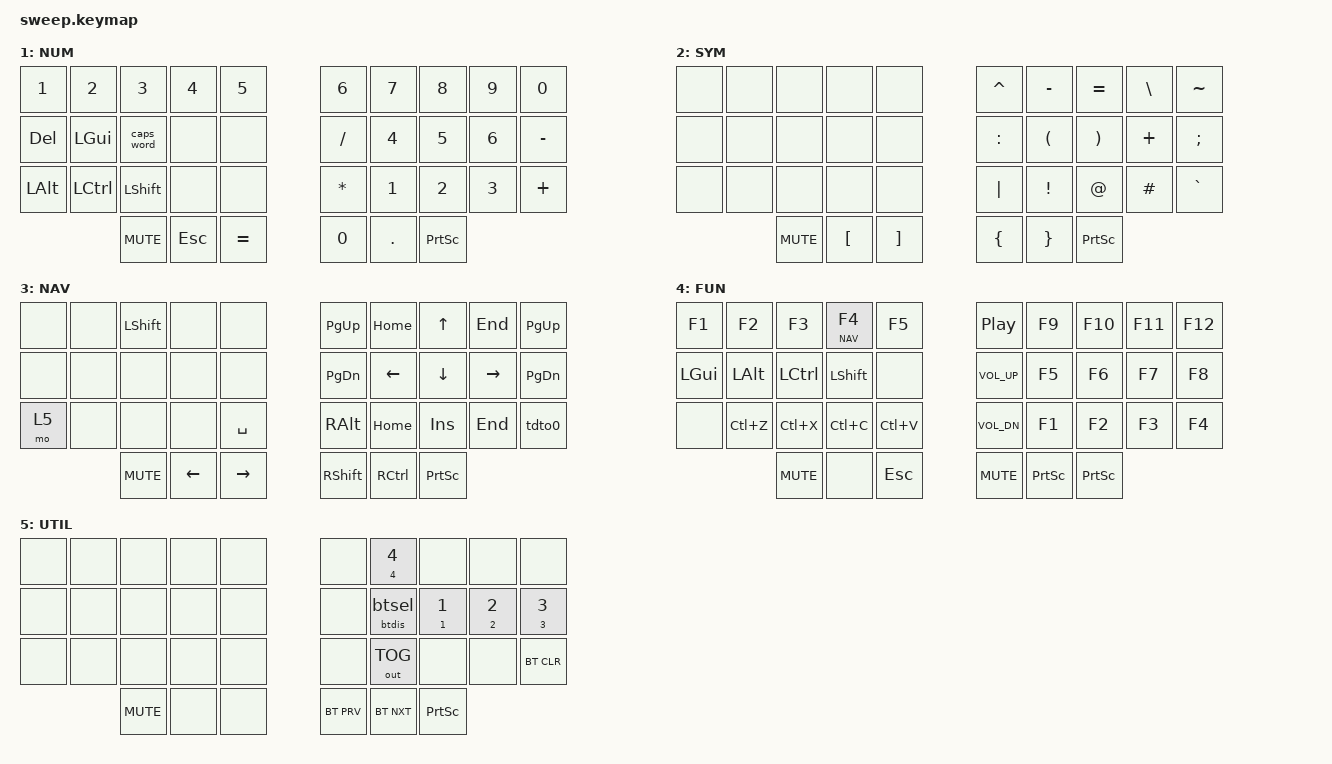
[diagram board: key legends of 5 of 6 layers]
// Copyright (c) 2022 The ZMK Contributors
// SPDX-License-Identifier: MIT
// #include <dt-bindings/zmk/rgb.h>

#define ZMK_POINTING_DEFAULT_MOVE_VAL 2500// 600
#define ZMK_POINTING_DEFAULT_SCRL_VAL 20// 10

#include <behaviors.dtsi>
#include <dt-bindings/zmk/bt.h>
#include <dt-bindings/zmk/keys.h>
#include <dt-bindings/zmk/outputs.h>
#include <dt-bindings/zmk/pointing.h>

#include "behaviors/character_map.dtsi"
#include "behaviors/report.dtsi"


#define ABC 0
#define NUM 1
#define SYM 2
#define NAV 3
#define FUN 4
#define UTIL 5

#define SPEED_POINTER 0
#define SPEED_SCROLL 1
#define SPEED_PREV 0
#define SPEED_NEXT 1
#define SPEED_RESET 2
#define SPEED_FINE_PREV 3
#define SPEED_FINE_NEXT 4
#define CIRQUE_MODE_RELATIVE 0
#define CIRQUE_MODE_ABSOLUTE 1
#define CIRQUE_MODE_TOGGLE 2

// Home row mods macro
#define HRML(k1,k2,k3,k4) &ht LGUI k1  &ht LALT k2  &ht LCTRL k3  &ht LSHFT k4
#define HRMR(k1,k2,k3,k4) &ht RSHFT k1  &ht RCTRL k2  &ht RALT k3  &ht RGUI k4

&sensors {
	left_encoder {
		triggers-per-rotation = <15>;
	};
	right_encoder {
		triggers-per-rotation = <45>;
	};
};

&glidepoint_listener {
	input-processors = <&pointer_processor 0 0 &drag_scroll_processor 1 8>;
};

/ {
	pointer_processor: pointer_processor {
		compatible = "zmk,input-processor-pointer-speed";
		#input-processor-cells = <2>;
		track-remainders;
		pointer-curve = "adaptive";
		pointer-curve-deadzone = <2>;
		pointer-curve-accel-multiplier = <1>;
		pointer-curve-accel-divisor = <12>;
		pointer-curve-max-delta = <120>;
		one-x-multiplier = <1>;
		one-x-divisor = <1>;
		min-percent = <10>;
		max-percent = <400>;
		initial-speed-position = <50>;
	};
	
	drag_scroll_processor: drag_scroll_processor {
		compatible = "zmk,input-processor-drag-scroll";
		#input-processor-cells = <2>;
		track-remainders;
		native-wheel-axis = "horizontal-when-enabled";
		scroll-min-step = <1>;
		one-x-multiplier = <1>;
		one-x-divisor = <1>;
		min-percent = <10>;
		max-percent = <1000>;
		initial-speed-position = <50>;
	};
	
	behaviors {
		drgscrl: drag_scroll {
			compatible = "zmk,behavior-drag-scroll";
			#binding-cells = <0>;
		};
	
		ptr_spd: pointing_speed {
			compatible = "zmk,behavior-pointing-speed";
			#binding-cells = <2>;
		};

		enc_ptr_spd: encoder_pointer_speed {
			compatible = "zmk,behavior-sensor-rotate";
			#sensor-binding-cells = <0>;
			bindings = <&ptr_spd SPEED_POINTER SPEED_PREV>, <&ptr_spd SPEED_POINTER SPEED_NEXT>;
		};

		enc_scrl_spd: encoder_scroll_speed {
			compatible = "zmk,behavior-sensor-rotate";
			#sensor-binding-cells = <0>;
			bindings = <&ptr_spd SPEED_SCROLL SPEED_PREV>, <&ptr_spd SPEED_SCROLL SPEED_NEXT>;
		};

		crq_mode: crqm {
			compatible = "zmk,behavior-cirque-mode";
			#binding-cells = <1>;
		};

		sel_x: select_x {
			compatible = "zmk,behavior-hold-tap";
			#binding-cells = <2>;
			flavor = "tap-preferred";
			tapping-term-ms = <200>;
			quick-tap-ms = <150>;
			require-prior-idle-ms = <125>;
			bindings = <&mkp>, <&kp>;
		};
		
		ds_z: drag_scroll_z {
			compatible = "zmk,behavior-hold-tap";
			#binding-cells = <2>;
			flavor = "tap-preferred";
			tapping-term-ms = <200>;
			quick-tap-ms = <150>;
			require-prior-idle-ms = <125>;
			bindings = <&drgscrl>, <&kp>;
		};

		ht: hold_tap {
			label = "hold_tap";
            compatible = "zmk,behavior-hold-tap";
            #binding-cells = <2>;
            flavor = "tap-preferred";
            tapping-term-ms = <180>;
            quick-tap-ms = <100>;
            require-prior-idle-ms = <100>;
            bindings = <&kp>, <&kp>;
        };
        btht: bluetooth_hold_tap {
            compatible = "zmk,behavior-hold-tap";
            #binding-cells = <2>;
            flavor = "tap-preferred";
            tapping-term-ms = <2000>;
            require-prior-idle-ms = <100>;
            bindings = <&btdis>, <&btsel>;
        };
        tdto0: tap_dance_to_layer_0 {
            compatible = "zmk,behavior-tap-dance";
            #binding-cells = <0>;
            tapping-term-ms = <200>;
            bindings = <&none>, <&to 0>;
        };
		mmv {
			acceleration-exponent = <1>;// 1
			time-to-max-speed-ms = <300>;// 40
			delay-ms = <0>;// 0
		};
		msc {
			acceleration-exponent = <0>;// 0
			time-to-max-speed-ms = <40>;// 500
			delay-ms = <0>;// 10
		};
	};
//End of behaviors

    macros {
        btsel: bluetooth_select {
            compatible = "zmk,behavior-macro-one-param";
            #binding-cells = <1>;
            bindings
                = <&macro_param_1to2>
                , <&macro_tap &bt BT_SEL MACRO_PLACEHOLDER>
                , <&macro_tap &out OUT_BLE>
                ;
        };
        btdis: bluetooth_disconnect {
            compatible = "zmk,behavior-macro-one-param";
            #binding-cells = <1>;
            bindings
                = <&macro_param_1to2>
                , <&macro_tap &bt BT_DISC MACRO_PLACEHOLDER>
                ;
        };
    };
//End of macros
	
	conditional_layers {
		compatible = "zmk,conditional-layers";
		
		tri_layer {
			if-layers = <NAV FUN>;
			then-layer = <UTIL>;
		};
	};

	combos {
		compatible = "zmk,combos";

		combo_fp_left_click {
			timeout-ms = <25>;
			require-prior-idle-ms = <125>;
			key-positions = <12 13>;
			layers = <ABC NUM NAV>;
			bindings = <&mkp RCLK>;
		};

		combo_cv_right_click {
			timeout-ms = <25>;
			require-prior-idle-ms = <125>;
			key-positions = <22 23>;
			layers = <ABC NUM NAV>;
			bindings = <&mkp RCLK>;
		};
        combo_caps_word {
            timeout-ms = <30>;
            key-positions = <2 3>;
            bindings = <&caps_word>;
        };
        combo_del {
            timeout-ms = <30>;
            key-positions = <6 7>;
            bindings = <&kp DEL>;
        };
        combo_esc {
            timeout-ms = <30>;
            key-positions = <0 1>;
            bindings = <&kp ESC>;
        };
        combo_navlock {
            timeout-ms = <30>;
            key-positions = <26 28>;
            bindings = <&to 3>;
        };
	};
//End of combos
	
	keymap {
		compatible = "zmk,keymap";

        default_layer {
			display-name = "ABC";
            bindings = <
        //╭──────────┬──────────┬──────────┬──────────┬──────────╮   ╭──────────┬──────────┬──────────┬──────────┬──────────╮
        //│  Q       │  W       │  F       │  P       │  B       │   │  J       │  L       │  U       │  Y       │ ' "      │
            &kp Q      &kp W      &kp F      &lt NAV P  &kp B          &kp J      &kp L      &kp U      &kp Y      &kp SQT
        //├──────────┼──────────┼──────────┼──────────┼──────────┤   ├──────────┼──────────┼──────────┼──────────┼──────────┤
        //│  A       │  R       │  S       │  T       │  G       │   │  M       │  N       │  E       │  I       │ O        │
            HRML(A,        R,         S,         T)     &kp G          &kp M      HRMR(N,        E,         I,        O)
        //├──────────┼──────────┼──────────┼──────────┼──────────┤   ├──────────┼──────────┼──────────┼──────────┼──────────┤
        //│  Z       │  X       │  C       │  D       │  V       │   │  K       │  H       │ , <      │ . >      │ / ?      │
            &lt FUN Z  &kp X      &lt SYM C  &lt NUM D  &kp V          &kp K      &kp H      &kp COMMA  &kp DOT    &kp FSLH
        //╰──────────┴──────────┴──────────┼──────────┼──────────┤   ├──────────┼──────────┼──────────┴──────────┴──────────╯
                        		 &kp C_MUTE  &kp TAB    &kp ENTER      &kp SPACE  &kp BSPC   &kp PSCRN
        //                      ╰──────────┴──────────┴──────────╯   ╰──────────┴──────────┴──────────╯
            >;
			sensor-bindings = <&inc_dec_kp C_VOL_DN C_VOL_UP &inc_dec_kp LEFT RIGHT>;
        };
		
        num_layer {
			display-name = "NUM";
            bindings = <
        //╭──────────┬──────────┬──────────┬──────────┬──────────╮   ╭──────────┬──────────┬──────────┬──────────┬──────────╮
        //│ 1        │ 2        │ 3        │ 4        │ 5        │   │ 6        │ 7        │ 8        │ 9        │  0       │
            &kp N1     &kp N2     &kp N3     &kp N4     &kp N5         &kp N6     &kp N7     &kp N8     &kp N9     &kp N0
        //├──────────┼──────────┼──────────┼──────────┼──────────┤   ├──────────┼──────────┼──────────┼──────────┼──────────┤
        //│ DELETE   │ WINDERS  │ CAPS     │          │          │   │ / ?      │ 4        │ 5        │ 6        │  -       │
            &kp DEL    &kp LGUI  &caps_word   &none      &none         &kp FSLH   &kp N4     &kp N5     &kp N6     &kp MINUS
        //├──────────┼──────────┼──────────┼──────────┼──────────┤   ├──────────┼──────────┼──────────┼──────────┼──────────┤
        //│          │          │          │This Layer│          │   │   *      │ 1        │ 2        │ 3        │  +       │
           &kp LALT   &kp LCTRL  &kp LSHFT   &none      &none         &kp ASTRK   &kp N1     &kp N2     &kp N3     &kp PLUS
        //╰──────────┴──────────┴──────────┼──────────┼──────────┤   ├──────────┼──────────┼──────────┴──────────┴──────────╯
                                 &kp C_MUTE  &kp ESC    &kp EQUAL       &kp N0     &kp DOT    &kp PSCRN
        //                      ╰──────────┴──────────┴──────────╯   ╰──────────┴──────────┴──────────╯
            >;
			sensor-bindings = <&inc_dec_kp C_VOL_DN C_VOL_UP &inc_dec_kp C_BRI_DEC C_BRI_UP>;
        };

        sym_layer {
			display-name = "SYM";
            bindings = <
        //╭──────────┬──────────┬──────────┬──────────┬──────────╮   ╭──────────┬──────────┬──────────┬──────────┬──────────╮
        //│          │          │          │          │          │   │  ^       │  -       │  =       │  \       │  ~       │
            &none      &none      &none     &none       &none          &kp CARET  &kp MINUS &kp EQUAL   &kp BSLH   &kp TILDE
        //├──────────┼──────────┼──────────┼──────────┼──────────┤   ├──────────┼──────────┼──────────┼──────────┼──────────┤
        //│          │          │          │          │          │   │  :       │  (       │  )       │  +       │  ;       │
            &none      &none     &none      &none       &none          &kp COLON  &kp LPAR   &kp RPAR   &kp PLUS   &kp SEMI
        //├──────────┼──────────┼──────────┼──────────┼──────────┤   ├──────────┼──────────┼──────────┼──────────┼──────────┤
        //│          │          │This Layer│ Not Del  │          │   │    │     │  !       │  @       │  #       │  `       │ Delete collided with num_layer LSHIFT
            &none      &none      &none      &none      &none         &kp PIPE    &kp EXCL   &kp AT     &kp HASH   &kp GRAVE
        //╰──────────┴──────────┴──────────┼──────────┼──────────┤   ├──────────┼──────────┼──────────┴──────────┴──────────╯
                                 &kp C_MUTE  &kp LBKT    &kp RBKT      &kp LBRC   &kp RBRC   &kp PSCRN
        //                      ╰──────────┴──────────┴──────────╯   ╰──────────┴──────────┴──────────╯
            >;
			sensor-bindings = <&inc_dec_kp C_VOL_DN C_VOL_UP &inc_dec_kp C_BRI_DEC C_BRI_UP>;
        };

		nav_layer {
			display-name = "NAV";
            bindings = <
        //╭──────────┬──────────┬──────────┬──────────┬──────────╮   ╭──────────┬──────────┬──────────┬──────────┬──────────╮
        //│          │          │ Shift    │This Layer│          │   │ Page Up  │ Home     │    UP    │ End      │ Page Up  │
           &none      &none       &kp LSHFT  &none      &none         &kp PG_UP   &kp HOME    &kp UP    &kp END    &kp PG_UP
        //├──────────┼──────────┼──────────┼──────────┼──────────┤   ├──────────┼──────────┼──────────┼──────────┼──────────┤
        //│          │          │          │          │          │   │ Page Down│  LEFT    │   DOWN   │  RIGHT   │ Page Down│
           &none      &none       &none       &none     &none         &kp PG_DN   &kp LEFT   &kp DOWN   &kp RIGHT  &kp PG_DN 
        //├──────────┼──────────┼──────────┼──────────┼──────────┤   ├──────────┼──────────┼──────────┼──────────┼──────────┤
        //│          │          │          │          │          │   │ Alt      │ Home     │ Insert   │ End      │Dbl tap L0│
           &mo 5      &none       &none       &none     &kp SPACE      &kp RALT   &kp HOME   &kp INS    &kp END    &tdto0
        //╰──────────┴──────────┴──────────┼──────────┼──────────┤   ├──────────┼──────────┼──────────┴──────────┴──────────╯
                                 &kp C_MUTE  &kp LEFT   &kp RIGHT     &kp RSHFT  &kp RCTRL  &kp PSCRN
        //                      ╰──────────┴──────────┴──────────╯   ╰──────────┴──────────┴──────────╯
            >;
			sensor-bindings = <&inc_dec_kp C_VOL_DN C_VOL_UP &inc_dec_kp LEFT RIGHT>;
        };

		fun_layer {
			display-name = "FUN";
            bindings = <
        //╭──────────┬──────────┬──────────┬──────────┬──────────╮   ╭──────────┬──────────┬──────────┬──────────┬──────────╮
        //│          │          │          │          │          │   │Play/Pause│          │          │          │          │
           &kp F1      &kp F2     &kp F3     &lt NAV F4   &kp F5         &kp C_PP    &kp F9    &kp F10    &kp F11    &kp F12
        //├──────────┼──────────┼──────────┼──────────┼──────────┤   ├──────────┼──────────┼──────────┼──────────┼──────────┤
        //│          │          │          │          │          │   │ Volume + │          │          │          │          │
           &kp LGUI   &kp LALT   &kp LCTRL  &kp LSHFT   &none        &kp C_VOL_UP  &kp F5    &kp F6     &kp F7     &kp F8
        //├──────────┼──────────┼──────────┼──────────┼──────────┤   ├──────────┼──────────┼──────────┼──────────┼──────────┤
        //│This Layer│  Undo    │  Cut     │  Copy    │  Paste   │   │ Volume - │          │          │          │          │
           &none      &kp LC(Z)  &kp LC(X)  &kp LC(C)   &kp LC(V)    &kp C_VOL_DN  &kp F1    &kp F2     &kp F3     &kp F4   
        //╰──────────┴──────────┴──────────┼──────────┼──────────┤   ├──────────┼──────────┼──────────┴──────────┴──────────╯
                                 &kp C_MUTE   &none     &kp ESC       &kp C_MUTE  &kp PSCRN  &kp PSCRN
        //                      ╰──────────┴──────────┴──────────╯   ╰──────────┴──────────┴──────────╯
            >;
			sensor-bindings = <&inc_dec_kp C_VOL_DN C_VOL_UP &inc_dec_kp C_BRI_DEC C_BRI_UP>;
        };

        util_layer {
			display-name = "UTIL";
            bindings = <
        //╭──────────┬──────────┬──────────┬──────────┬──────────╮   ╭──────────┬──────────────┬──────────────┬──────────────┬──────────────╮
        //│          │          │          │This Layer│          │   │          │ Guest        │              │              │              │
           &none      &none       &none       &none     &none          &none      &btht 4 4      &none           &none         &none
        //├──────────┼──────────┼──────────┼──────────┼──────────┤   ├──────────┼──────────────┼──────────────┼──────────────┼──────────────┤
        //│          │          │          │          │          │   │          │ Big Lappy    │ Work Lappy   │ Tiny Lappy   │   Phone      │
           &none      &none       &none       &none     &none          &none      &btht 0 0      &btht 1 1      &btht 2 2      &btht 3 3
        //├──────────┼──────────┼──────────┼──────────┼──────────┤   ├──────────┼──────────────┼──────────────┼──────────────┼──────────────┤
        //│This Layer│          │          │          │          │   │          │ USB/BLE      │              │              │Clear Profile │
           &none      &none       &none       &none     &none          &none      &out OUT_TOG    &none           &none        &bt BT_CLR
        //╰──────────┴──────────┴──────────┼──────────┼──────────┤   ├──────────┼──────────────┼──────────────┴──────────────┴──────────────╯
                                 &kp C_MUTE   &none     &none         &bt BT_PRV &bt BT_NXT &kp PSCRN
        //                      ╰──────────┴──────────┴──────────╯   ╰──────────┴──────────┴──────────╯
            >;
			sensor-bindings = <&inc_dec_kp C_VOL_DN C_VOL_UP &inc_dec_kp C_BRI_DEC C_BRI_UP>;
        };

	};
//End of Keymap



};
